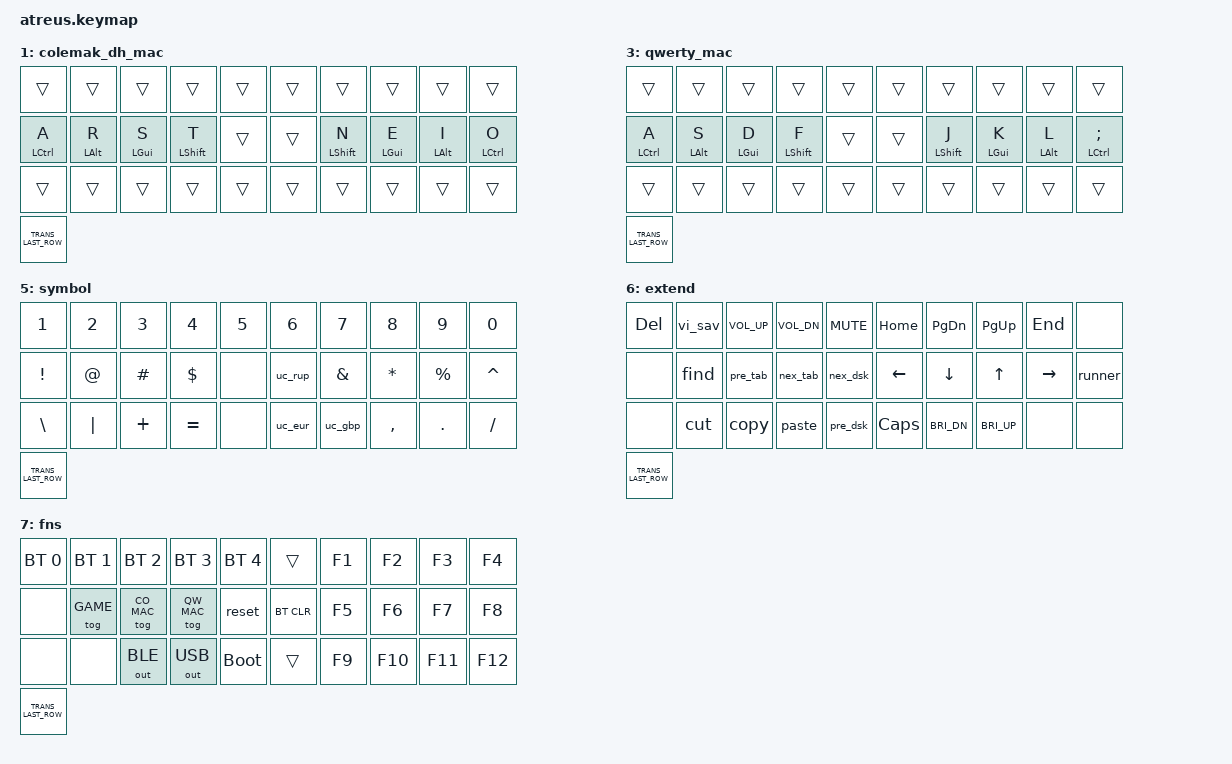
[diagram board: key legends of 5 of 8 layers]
/*
 * Copyright (c) 2021 The ZMK Contributors
 *
 * SPDX-License-Identifier: MIT
 */

#include "hold_tap_behaviors.dtsi"
#include "combos.dtsi"
#include <dt-bindings/zmk/keys.h>
#include <dt-bindings/zmk/bt.h>
#include <dt-bindings/zmk/outputs.h>

// Layers
#define CO 0
#define CO_MAC 1
#define QW 2
#define QW_MAC 3
#define GAME 4
#define SY 5
#define EX 6
#define FN 7

#define TRANS_LAST_ROW_HALF &trans &trans &trans &trans &trans &trans
#define TRANS_LAST_ROW TRANS_LAST_ROW_HALF TRANS_LAST_ROW_HALF

/ {
  macros {
    ZMK_MACRO(uc_gbp  , tap-ms=<0>; wait-ms=<0>; bindings = <&kp LC(LS(U))>, <&kp N0 &kp N0 &kp A &kp N3>, <&kp SPACE>;)
    ZMK_MACRO(uc_eur  , tap-ms=<0>; wait-ms=<0>; bindings = <&kp LC(LS(U))>, <&kp N2 &kp N0 &kp A &kp C>, <&kp SPACE>;)
    ZMK_MACRO(uc_rup  , tap-ms=<0>; wait-ms=<0>; bindings = <&kp LC(LS(U))>, <&kp N2 &kp N0 &kp B &kp N9>, <&kp SPACE>;)
    ZMK_MACRO(vi_sav  , tap-ms=<0>; wait-ms=<0>; bindings = <&kp COLON &kp W>, <&kp RET>;)
    ZMK_MACRO(runner  , bindings = <&kp LC(SPACE)>;)
    ZMK_MACRO(find    , bindings = <&kp LC(F)>;)
    ZMK_MACRO(pre_tab , bindings = <&kp LC(LS(TAB))>;)
    ZMK_MACRO(nex_tab , bindings = <&kp LC(TAB)>;)
    ZMK_MACRO(pre_dsk , bindings = <&kp LC(LG(LEFT))>;)
    ZMK_MACRO(nex_dsk , bindings = <&kp LC(LG(RIGHT))>;)
    ZMK_MACRO(tmux    , bindings = <&kp LC(B)>;)
    ZMK_MACRO(cut     , bindings = <&kp LC(X)>;)
    ZMK_MACRO(copy    , bindings = <&kp LC(C)>;)
    ZMK_MACRO(paste   , bindings = <&kp LC(V)>;)
  };

  keymap {
    compatible = "zmk,keymap";

      colemak_dh {
        bindings = <
          &kp Q       &hml LA(LGUI) W &hml LC(LGUI) F &hml LS(LGUI) P &kp B &kp J &hmr LS(LGUI) L &hmr LC(LGUI) U &hmr LA(LGUI) Y &hlr FN SEMI
          &hml LGUI A &hml LALT R     &hml LCTL S     &hml LSHFT T    &kp G &kp M &hmr LSHFT N    &hmr LCTL E     &hmr LALT I     &hmr LGUI O
          &kp Z       &kp X           &kp C           &kp D           &kp V &kp K &kp H           &kp COMMA       &kp DOT         &kp FSLH

          &mo FN &kp UNDER &kp MINUS &kp BSPC &hrl FN SPACE &htl EX ESC /**/ &htl SY RET &kp LSHFT &kp TAB &kp SQT &kp DQT &mo FN
        >;
      };

      colemak_dh_mac {
        bindings = <
          &trans      &trans      &trans      &trans       &trans &trans &trans       &trans      &trans      &trans
          &hml LCTL A &hml LALT R &hml LGUI S &hml LSHFT T &trans &trans &hmr LSHFT N &hmr LGUI E &hmr LALT I &hmr LCTL O
          &trans      &trans      &trans      &trans       &trans &trans &trans       &trans      &trans      &trans

          TRANS_LAST_ROW
        >;
      };

      qwerty {
        bindings = <
          &kp Q       &hml LA(LGUI) W &hml LC(LGUI) E &hml LS(LGUI) R &kp T  &kp Y &hmr LS(LGUI) U &hmr LC(LGUI) I &hmr LA(LGUI) O &hlr FN P
          &hml LGUI A &hml LALT S     &hml LCTL D     &hml LSHFT F    &trans &kp H &hmr LSHFT J    &hmr LCTL K     &hmr LALT L     &hmr LGUI SEMI
          &kp Z       &kp X           &kp C           &kp V           &kp B  &kp N &kp M           &kp COMMA       &kp DOT         &kp FSLH

          &mo FN &kp UNDER &kp MINUS &kp BSPC &hrl FN SPACE &htl EX ESC /**/ &htl SY RET &kp LSHFT &kp TAB &kp SQT &kp DQT &mo FN
        >;
      };

      qwerty_mac {
        bindings = <
          &trans      &trans      &trans      &trans       &trans &trans &trans       &trans      &trans      &trans
          &hml LCTL A &hml LALT S &hml LGUI D &hml LSHFT F &trans &trans &hmr LSHFT J &hmr LGUI K &hmr LALT L &hmr LCTL SEMI
          &trans      &trans      &trans      &trans       &trans &trans &trans       &trans      &trans      &trans

          TRANS_LAST_ROW
        >;
      };

      // Gaming Layer
      game {
        bindings = <
          &kp TAB  &kp Q &kp W &kp E &kp R &none &kp N7 &kp N8 &kp N9 &kp N0
          &kp LCTL &kp A &kp S &kp D &kp F &none &kp N4 &kp N5 &kp N6 &mo FN
          &kp Z    &kp X &kp C &kp V &kp B &none &kp N1 &kp N2 &kp N3 &tog GAME

          &mo FN &mo FN &kp ESC &kp LSHFT &kp SPACE &kp LALT /**/ &none &kp RET &none &none &none &mo FN
        >;
      };


      // Symbol Layer
      /* symbol {
        bindings = <
          &kp DOT   &kp N7 &kp N8 &kp N9 &kp N0   &none &uc_gbp  &none    &kp PIPE  &kp BSLH
          &kp MINUS &kp N4 &kp N5 &kp N6 &kp PLUS &none &kp EXCL &kp AT   &kp HASH  &kp DLLR
          &kp STAR  &kp N1 &kp N2 &kp N3 &kp FSLH &none &kp AMPS &kp STAR &kp PRCNT &kp CARET

          TRANS_LAST_ROW
        >;
      }; */

      // Symbol Layer with numbers on the top layer
      symbol {
        bindings = <
          &kp N1   &kp N2   &kp N3   &kp N4   &kp N5 &kp N6  &kp N7   &kp N8    &kp N9    &kp N0
          &kp EXCL &kp AT   &kp HASH &kp DLLR &none  &uc_rup &kp AMPS &kp STAR  &kp PRCNT &kp CARET
          &kp BSLH &kp PIPE &kp PLUS &kp EQL  &none  &uc_eur &uc_gbp  &kp COMMA &kp DOT   &kp FSLH

          TRANS_LAST_ROW
          >;
      };

      // Extend Layer with Macros and Special Keys
      extend {
        bindings = <
          &kp DEL &vi_sav &kp C_VOL_UP &kp C_VOL_DN &kp C_MUTE &kp HOME &kp PG_DN    &kp PG_UP    &kp END   &none
          &none   &find   &pre_tab     &nex_tab     &nex_dsk   &kp LEFT &kp DOWN     &kp UP       &kp RIGHT &runner
          &none   &cut    &copy        &paste       &pre_dsk   &kp CAPS &kp C_BRI_DN &kp C_BRI_UP &none     &none

          TRANS_LAST_ROW
          >;
      };

      // Adjustments layer and Fn Keys
      fns {
        bindings = <
          &bt BT_SEL 0 &bt BT_SEL 1 &bt BT_SEL 2 &bt BT_SEL 3 &bt BT_SEL 4 &trans     &kp F1 &kp F2  &kp F3  &kp F4
          &none        &tog GAME    &tog CO_MAC  &tog QW_MAC  &reset       &bt BT_CLR &kp F5 &kp F6  &kp F7  &kp F8
          &none        &none        &out OUT_BLE &out OUT_USB &bootloader  &trans     &kp F9 &kp F10 &kp F11 &kp F12

          TRANS_LAST_ROW
          >;
      };
  };
};

// vi:ft=dts
